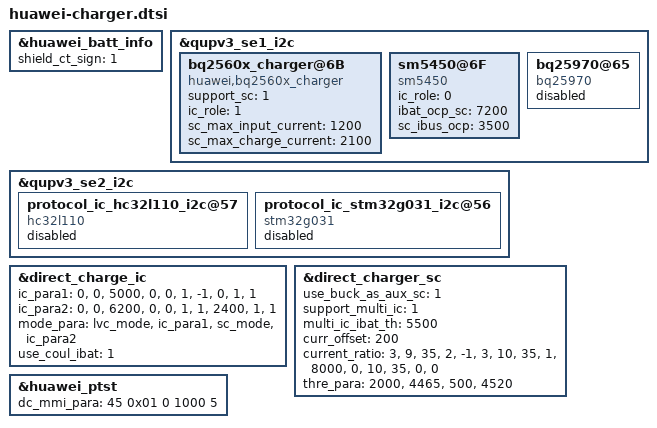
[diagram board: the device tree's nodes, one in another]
&huawei_batt_info {
	shield_ct_sign = <1>;
};

&qupv3_se1_i2c {
	status = "ok";
	bq2560x_charger@6B{
		compatible = "huawei,bq2560x_charger";
		support_sc = <1>;
		ic_role = <1>;
		sc_max_input_current = <1200>;
		sc_max_charge_current  = <2100>;
		status = "ok";
	};

	sm5450@6F{
		compatible = "sm5450";
		ic_role = <0>;
		ibat_ocp_sc = <7200>;
		sc_ibus_ocp = <3500>;
		status = "ok";
	};

	bq25970@65 {
		compatible = "bq25970";
		status = "disabled";
	};
};

&qupv3_se2_i2c {
	status = "ok";
	protocol_ic_hc32l110_i2c@57 {
		compatible = "hc32l110";
		status = "disabled";
	};

	protocol_ic_stm32g031_i2c@56 {
		compatible = "stm32g031";
		status = "disabled";
	};
};

&direct_charge_ic {
	/* ic_index  path_index  max_ibat  ibat_sample_point  vbat_sample_point */
	ic_para1 =
		"0", "0", "5000", "0", "0",
		"1", "-1", "0", "1", "1";
	ic_para2 =
		"0", "0", "6200", "0", "0",
		"1", "1", "2400", "1", "1";
	mode_para =
		"lvc_mode", "ic_para1",
		"sc_mode", "ic_para2";
	use_coul_ibat = <1>;
	status = "ok";
};

&direct_charger_sc{
	use_buck_as_aux_sc = <1>;
	support_multi_ic = <1>;
	multi_ic_ibat_th = <5500>;
	curr_offset = <200>;
	current_ratio =
		"3", "9", "35", "2", "-1",
		"3", "10", "35", "1", "8000",
		"0", "10", "35", "0", "0";
	thre_para =
		"2000", "4465",
		"500", "4520";
};

&huawei_ptst {
	dc_mmi_para = <45 0x01 0 1000 5>;
	status = "ok";
};
